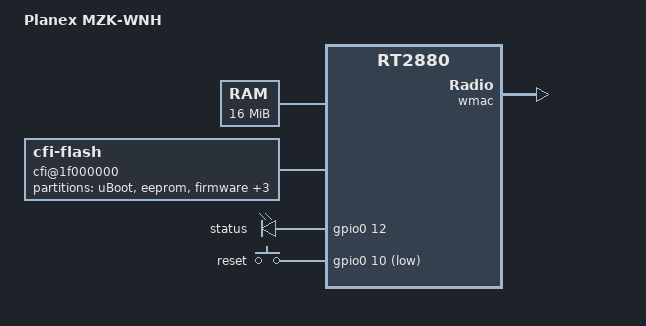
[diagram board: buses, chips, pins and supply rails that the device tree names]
/dts-v1/;

#include "rt2880.dtsi"

/ {
	compatible = "MZK-WNH", "ralink,rt2880-soc";
	model = "Planex MZK-WNH";

	memory@8000000 {
		device_type = "memory";
		reg = <0x08000000 0x1000000>;
	};

	cfi@1f000000 {
		compatible = "cfi-flash";
		reg = <0x1f000000 0x800000>;
		bank-width = <2>;
		device-width = <2>;
		#address-cells = <1>;
		#size-cells = <1>;

		partition@0 {
			label = "uBoot";
			reg = <0x0 0x40000>;
			read-only;
		};
		partition@40000 {
			label = "eeprom";
			reg = <0x40000 0x10000>;
			read-only;
		};

		kernel: partition@50000 {
			label = "firmware";
			reg = <0x00050000 0x00390000>;
			read-only;
		};
		rootfs: partition@160000 {
			label = "upgrade";
			reg = <0x00050000 0x00390000>;
		};
		nvram: partition@3e00000 {
			label = "NVRAM";
			reg = <0x003e0000 0x00010000>;
			read-only;
		};
		factory: partition@3f00000 {
			label = "FACTORY";
			reg = <0x003f0000 0x00010000>;
			read-only;
		};

	};

	gpio-leds {
		compatible = "gpio-leds";

		status {
			label = "status";
			gpios = <&gpio0 12 0>;
		};

	};
	gpio-keys-polled {
		compatible = "gpio-keys-polled";
		#address-cells = <1>;
		#size-cells = <0>;
		poll-interval = <20>;

		reset {
			label = "reset";
			gpios = <&gpio0 10 1>;
			linux,code = <0x198>;
		};

	};

	ip17x@0 {
		compatible = "icplus,ip17x";
	};

};

&ethernet {
	mtd-mac-address = <&factory 0x28>;
};

&wmac {
	ralink,mtd-eeprom = <&factory 0>;
};
